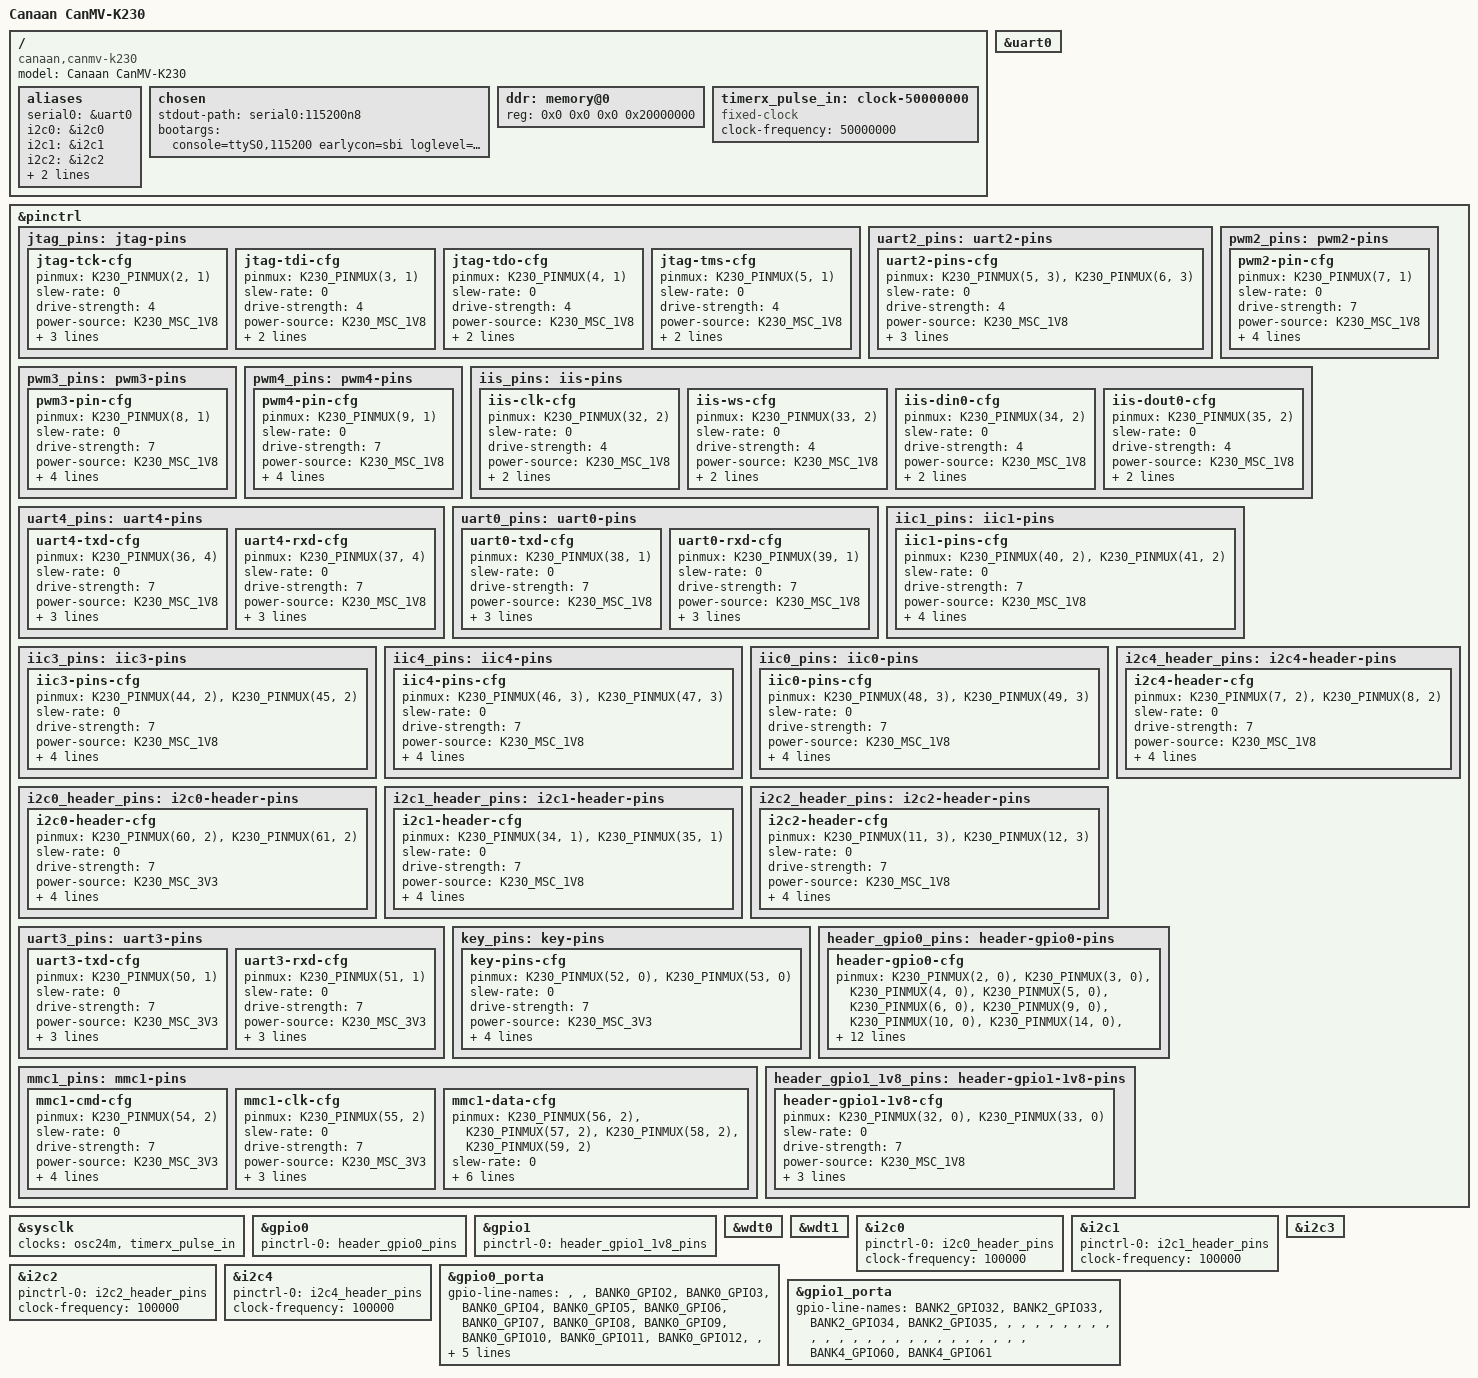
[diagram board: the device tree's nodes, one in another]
// SPDX-License-Identifier: GPL-2.0 OR MIT
/*
 * Copyright (C) 2024 Yangyu Chen <cyy@cyyself.name>
 */

#include "k230.dtsi"

/ {
	model = "Canaan CanMV-K230";
	compatible = "canaan,canmv-k230", "canaan,kendryte-k230";

	aliases {
		serial0 = &uart0;
		i2c0 = &i2c0;
		i2c1 = &i2c1;
		i2c2 = &i2c2;
		i2c3 = &i2c3;
		i2c4 = &i2c4;
	};

	chosen {
		stdout-path = "serial0:115200n8";
		bootargs = "console=ttyS0,115200 earlycon=sbi loglevel=8 ignore_loglevel";
	};

	ddr: memory@0 {
		device_type = "memory";
		reg = <0x0 0x0 0x0 0x20000000>;
	};

	timerx_pulse_in: clock-50000000 {
		compatible = "fixed-clock";
		#clock-cells = <0>;
		clock-frequency = <50000000>;
	};
};

&uart0 {
	status = "okay";
};

&pinctrl {
	jtag_pins: jtag-pins {
		jtag-tck-cfg {
			pinmux = <K230_PINMUX(2, 1)>;
			slew-rate = <0>;
			drive-strength = <4>;
			power-source = <K230_MSC_1V8>;
			input-enable;
			bias-pull-down;
			input-schmitt-enable;
		};

		jtag-tdi-cfg {
			pinmux = <K230_PINMUX(3, 1)>;
			slew-rate = <0>;
			drive-strength = <4>;
			power-source = <K230_MSC_1V8>;
			input-enable;
			bias-disable;
		};

		jtag-tdo-cfg {
			pinmux = <K230_PINMUX(4, 1)>;
			slew-rate = <0>;
			drive-strength = <4>;
			power-source = <K230_MSC_1V8>;
			output-enable;
			bias-disable;
		};

		jtag-tms-cfg {
			pinmux = <K230_PINMUX(5, 1)>;
			slew-rate = <0>;
			drive-strength = <4>;
			power-source = <K230_MSC_1V8>;
			input-enable;
			bias-pull-up;
		};
	};

	uart2_pins: uart2-pins {
		uart2-pins-cfg {
			pinmux = <K230_PINMUX(5, 3)>, /* uart2 txd */
				 <K230_PINMUX(6, 3)>; /* uart2 rxd */
			slew-rate = <0>;
			drive-strength = <4>;
			power-source = <K230_MSC_1V8>;
			input-enable;
			output-enable;
			bias-disable;
		};
	};

	pwm2_pins: pwm2-pins {
		pwm2-pin-cfg {
			pinmux = <K230_PINMUX(7, 1)>;
			slew-rate = <0>;
			drive-strength = <7>;
			power-source = <K230_MSC_1V8>;
			input-enable;
			output-enable;
			bias-disable;
			input-schmitt-enable;
		};
	};

	pwm3_pins: pwm3-pins {
		pwm3-pin-cfg {
			pinmux = <K230_PINMUX(8, 1)>;
			slew-rate = <0>;
			drive-strength = <7>;
			power-source = <K230_MSC_1V8>;
			input-enable;
			output-enable;
			bias-disable;
			input-schmitt-enable;
		};
	};

	pwm4_pins: pwm4-pins {
		pwm4-pin-cfg {
			pinmux = <K230_PINMUX(9, 1)>;
			slew-rate = <0>;
			drive-strength = <7>;
			power-source = <K230_MSC_1V8>;
			input-enable;
			output-enable;
			bias-disable;
			input-schmitt-enable;
		};
	};

	iis_pins: iis-pins {
		iis-clk-cfg {
			pinmux = <K230_PINMUX(32, 2)>;
			slew-rate = <0>;
			drive-strength = <4>;
			power-source = <K230_MSC_1V8>;
			output-enable;
			bias-disable;
		};

		iis-ws-cfg {
			pinmux = <K230_PINMUX(33, 2)>;
			slew-rate = <0>;
			drive-strength = <4>;
			power-source = <K230_MSC_1V8>;
			output-enable;
			bias-disable;
		};

		iis-din0-cfg {
			pinmux = <K230_PINMUX(34, 2)>;
			slew-rate = <0>;
			drive-strength = <4>;
			power-source = <K230_MSC_1V8>;
			input-enable;
			bias-disable;
		};

		iis-dout0-cfg {
			pinmux = <K230_PINMUX(35, 2)>;
			slew-rate = <0>;
			drive-strength = <4>;
			power-source = <K230_MSC_1V8>;
			output-enable;
			bias-disable;
		};
	};

	uart4_pins: uart4-pins {
		uart4-txd-cfg {
			pinmux = <K230_PINMUX(36, 4)>;
			slew-rate = <0>;
			drive-strength = <7>;
			power-source = <K230_MSC_1V8>;
			output-enable;
			bias-disable;
			input-schmitt-enable;
		};

		uart4-rxd-cfg {
			pinmux = <K230_PINMUX(37, 4)>;
			slew-rate = <0>;
			drive-strength = <7>;
			power-source = <K230_MSC_1V8>;
			input-enable;
			bias-disable;
			input-schmitt-enable;
		};
	};

	uart0_pins: uart0-pins {
		uart0-txd-cfg {
			pinmux = <K230_PINMUX(38, 1)>;
			slew-rate = <0>;
			drive-strength = <7>;
			power-source = <K230_MSC_1V8>;
			output-enable;
			bias-disable;
			input-schmitt-enable;
		};

		uart0-rxd-cfg {
			pinmux = <K230_PINMUX(39, 1)>;
			slew-rate = <0>;
			drive-strength = <7>;
			power-source = <K230_MSC_1V8>;
			input-enable;
			bias-disable;
			input-schmitt-enable;
		};
	};

	iic1_pins: iic1-pins {
		iic1-pins-cfg {
			pinmux = <K230_PINMUX(40, 2)>, /* iic1 scl */
				 <K230_PINMUX(41, 2)>; /* iic1 sda */
			slew-rate = <0>;
			drive-strength = <7>;
			power-source = <K230_MSC_1V8>;
			input-enable;
			output-enable;
			bias-pull-up;
			input-schmitt-enable;
		};
	};

	iic3_pins: iic3-pins {
		iic3-pins-cfg {
			pinmux = <K230_PINMUX(44, 2)>, /* iic3 scl */
				 <K230_PINMUX(45, 2)>; /* iic3 sda */
			slew-rate = <0>;
			drive-strength = <7>;
			power-source = <K230_MSC_1V8>;
			input-enable;
			output-enable;
			bias-pull-up;
			input-schmitt-enable;
		};
	};

	iic4_pins: iic4-pins {
		iic4-pins-cfg {
			pinmux = <K230_PINMUX(46, 3)>, /* iic4 scl */
				 <K230_PINMUX(47, 3)>; /* iic4 sda */
			slew-rate = <0>;
			drive-strength = <7>;
			power-source = <K230_MSC_1V8>;
			input-enable;
			output-enable;
			bias-pull-up;
			input-schmitt-enable;
		};
	};

	iic0_pins: iic0-pins {
		iic0-pins-cfg {
			pinmux = <K230_PINMUX(48, 3)>, /* iic0 scl */
				 <K230_PINMUX(49, 3)>; /* iic0 sda */
			slew-rate = <0>;
			drive-strength = <7>;
			power-source = <K230_MSC_1V8>;
			input-enable;
			output-enable;
			bias-pull-up;
			input-schmitt-enable;
		};
	};

	i2c0_header_pins: i2c0-header-pins {
		i2c0-header-cfg {
			pinmux = <K230_PINMUX(60, 2)>,	/* JP1-34 I2C0_SCL */
				 <K230_PINMUX(61, 2)>;	/* JP1-36 I2C0_SDA */
			slew-rate = <0>;
			drive-strength = <7>;
			power-source = <K230_MSC_3V3>;
			input-enable;
			output-enable;
			bias-pull-up;
			input-schmitt-enable;
		};
	};

	i2c4_header_pins: i2c4-header-pins {
		i2c4-header-cfg {
			pinmux = <K230_PINMUX(7, 2)>,	/* JP1-12 I2C4_SCL */
				 <K230_PINMUX(8, 2)>;	/* JP1-13 I2C4_SDA */
			slew-rate = <0>;
			drive-strength = <7>;
			power-source = <K230_MSC_1V8>;
			input-enable;
			output-enable;
			bias-pull-up;
			input-schmitt-enable;
		};
	};

	i2c1_header_pins: i2c1-header-pins {
		i2c1-header-cfg {
			pinmux = <K230_PINMUX(34, 1)>,	/* JP1-32 I2C1_SCL */
				 <K230_PINMUX(35, 1)>;	/* JP1-33 I2C1_SDA */
			slew-rate = <0>;
			drive-strength = <7>;
			power-source = <K230_MSC_1V8>;
			input-enable;
			output-enable;
			bias-pull-up;
			input-schmitt-enable;
		};
	};

	i2c2_header_pins: i2c2-header-pins {
		i2c2-header-cfg {
			pinmux = <K230_PINMUX(11, 3)>,	/* JP1-16 I2C2_SCL */
				 <K230_PINMUX(12, 3)>;	/* JP1-17 I2C2_SDA */
			slew-rate = <0>;
			drive-strength = <7>;
			power-source = <K230_MSC_1V8>;
			input-enable;
			output-enable;
			bias-pull-up;
			input-schmitt-enable;
		};
	};

	uart3_pins: uart3-pins {
		uart3-txd-cfg {
			pinmux = <K230_PINMUX(50, 1)>;
			slew-rate = <0>;
			drive-strength = <7>;
			power-source = <K230_MSC_3V3>;
			output-enable;
			bias-disable;
			input-schmitt-enable;
		};

		uart3-rxd-cfg {
			pinmux = <K230_PINMUX(51, 1)>;
			slew-rate = <0>;
			drive-strength = <7>;
			power-source = <K230_MSC_3V3>;
			input-enable;
			bias-disable;
			input-schmitt-enable;
		};
	};

	key_pins: key-pins {
		key-pins-cfg {
			pinmux = <K230_PINMUX(52, 0)>, /* key0 */
				 <K230_PINMUX(53, 0)>; /* key1 */
			slew-rate = <0>;
			drive-strength = <7>;
			power-source = <K230_MSC_3V3>;
			input-enable;
			output-enable;
			bias-disable;
			input-schmitt-enable;
		};
	};

	mmc1_pins: mmc1-pins {
		mmc1-cmd-cfg {
			pinmux = <K230_PINMUX(54, 2)>;
			slew-rate = <0>;
			drive-strength = <7>;
			power-source = <K230_MSC_3V3>;
			input-enable;
			output-enable;
			bias-pull-up;
			input-schmitt-enable;
		};

		mmc1-clk-cfg {
			pinmux = <K230_PINMUX(55, 2)>;
			slew-rate = <0>;
			drive-strength = <7>;
			power-source = <K230_MSC_3V3>;
			output-enable;
			bias-disable;
			input-schmitt-enable;
		};

		mmc1-data-cfg {
			pinmux = <K230_PINMUX(56, 2)>, /* mmc1 data0 */
				 <K230_PINMUX(57, 2)>, /* mmc1 data1 */
				 <K230_PINMUX(58, 2)>, /* mmc1 data2 */
				 <K230_PINMUX(59, 2)>; /* mmc1 data3 */
			slew-rate = <0>;
			drive-strength = <7>;
			power-source = <K230_MSC_3V3>;
			input-enable;
			output-enable;
			bias-pull-up;
			input-schmitt-enable;
		};
	};

	/*
	 * JP1 40-pin header GPIOs.
	 *
	 * Default configuration: GPIO output with input readback enabled.
	 * The pad OE/IE bits are static; for input-only use remove
	 * "output-enable" and keep "input-enable".  For output-only use
	 * remove "input-enable".
	 *
	 * BANK0/BANK1/BANK2 pins are 1.8V only.  BANK4 GPIO60/61 are 3.3V
	 * and are muxed to I2C0 (JP1-34/36); they are not part of the GPIO
	 * header state.  JP1-12/13 (IO7/IO8) are I2C4, JP1-16/17
	 * (IO11/IO12) are I2C2, and JP1-32/33 (IO34/IO35) are I2C1 at
	 * 1.8V; those pins are not part of the GPIO header state either.
	 * IO9/IO10 remain GPIO.
	 * Do not drive 3.3V levels into the 1.8V pins.
	 */
	header_gpio0_pins: header-gpio0-pins {
		header-gpio0-cfg {
			pinmux = <K230_PINMUX(2, 0)>,	/* JP1-7  BANK0_GPIO2 */
				 <K230_PINMUX(3, 0)>,	/* JP1-8  BANK0_GPIO3 */
				 <K230_PINMUX(4, 0)>,	/* JP1-9  BANK0_GPIO4 */
				 <K230_PINMUX(5, 0)>,	/* JP1-10 BANK0_GPIO5 */
				 <K230_PINMUX(6, 0)>,	/* JP1-11 BANK0_GPIO6 */
				 <K230_PINMUX(9, 0)>,	/* JP1-14 BANK0_GPIO9 */
				 <K230_PINMUX(10, 0)>,	/* JP1-15 BANK0_GPIO10 */
				 <K230_PINMUX(14, 0)>,	/* JP1-18 BANK1_GPIO14 */
				 <K230_PINMUX(15, 0)>,	/* JP1-19 BANK1_GPIO15 */
				 <K230_PINMUX(16, 0)>,	/* JP1-20 BANK1_GPIO16 */
				 <K230_PINMUX(17, 0)>,	/* JP1-21 BANK1_GPIO17 */
				 <K230_PINMUX(18, 0)>,	/* JP1-22 BANK1_GPIO18 */
				 <K230_PINMUX(19, 0)>,	/* JP1-23 BANK1_GPIO19 */
				 <K230_PINMUX(26, 0)>,	/* JP1-24 BANK2_GPIO26 */
				 <K230_PINMUX(27, 0)>,	/* JP1-25 BANK2_GPIO27 */
				 <K230_PINMUX(28, 0)>,	/* JP1-26 BANK2_GPIO28 */
				 <K230_PINMUX(29, 0)>,	/* JP1-27 BANK2_GPIO29 */
				 <K230_PINMUX(30, 0)>,	/* JP1-28 BANK2_GPIO30 */
				 <K230_PINMUX(31, 0)>;	/* JP1-29 BANK2_GPIO31 */
			slew-rate = <0>;
			drive-strength = <7>;
			power-source = <K230_MSC_1V8>;
			input-enable;
			output-enable;
			bias-disable;
		};
	};

	header_gpio1_1v8_pins: header-gpio1-1v8-pins {
		header-gpio1-1v8-cfg {
			pinmux = <K230_PINMUX(32, 0)>,	/* JP1-30 BANK2_GPIO32 */
				 <K230_PINMUX(33, 0)>;	/* JP1-31 BANK2_GPIO33 */
			slew-rate = <0>;
			drive-strength = <7>;
			power-source = <K230_MSC_1V8>;
			input-enable;
			output-enable;
			bias-disable;
		};
	};

};


&sysclk {
	clocks = <&osc24m>, <&timerx_pulse_in>;
	clock-names = "osc24m", "timer-pulse-in";
};

&gpio0 {
	status = "okay";
	pinctrl-names = "default";
	pinctrl-0 = <&header_gpio0_pins>;
};

&gpio1 {
	status = "okay";
	pinctrl-names = "default";
	pinctrl-0 = <&header_gpio1_1v8_pins>;
};

&wdt0 {
	status = "okay";
};

&wdt1 {
	status = "okay";
};

&i2c0 {
	status = "okay";
	pinctrl-names = "default";
	pinctrl-0 = <&i2c0_header_pins>;
	clock-frequency = <100000>;
};

&i2c1 {
	status = "okay";
	pinctrl-names = "default";
	pinctrl-0 = <&i2c1_header_pins>;
	clock-frequency = <100000>;
};

&i2c2 {
	status = "okay";
	pinctrl-names = "default";
	pinctrl-0 = <&i2c2_header_pins>;
	clock-frequency = <100000>;
};

&i2c3 {
	status = "okay";
};

&i2c4 {
	status = "okay";
	pinctrl-names = "default";
	pinctrl-0 = <&i2c4_header_pins>;
	clock-frequency = <100000>;
};

/* JP1 40-pin header line names (offsets 0..31 on each port). */
&gpio0_porta {
	gpio-line-names =
		/* 0-1   */ "", "",
		/* 2-12  */ "BANK0_GPIO2", "BANK0_GPIO3", "BANK0_GPIO4",
			    "BANK0_GPIO5", "BANK0_GPIO6", "BANK0_GPIO7",
			    "BANK0_GPIO8", "BANK0_GPIO9", "BANK0_GPIO10",
			    "BANK0_GPIO11", "BANK0_GPIO12",
		/* 13    */ "",
		/* 14-19 */ "BANK1_GPIO14", "BANK1_GPIO15", "BANK1_GPIO16",
			    "BANK1_GPIO17", "BANK1_GPIO18", "BANK1_GPIO19",
		/* 20-25 */ "", "", "", "", "", "",
		/* 26-31 */ "BANK2_GPIO26", "BANK2_GPIO27", "BANK2_GPIO28",
			    "BANK2_GPIO29", "BANK2_GPIO30", "BANK2_GPIO31";
};

&gpio1_porta {
	gpio-line-names =
		/* 0-3   */ "BANK2_GPIO32", "BANK2_GPIO33",
			    "BANK2_GPIO34", "BANK2_GPIO35",
		/* 4-27  */ "", "", "", "", "", "", "", "", "", "", "", "",
			    "", "", "", "", "", "", "", "", "", "", "", "",
		/* 28-29 */ "BANK4_GPIO60", "BANK4_GPIO61";
};
